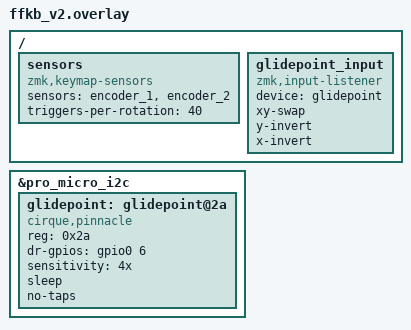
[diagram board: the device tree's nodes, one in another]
#include <dt-bindings/zmk/input_transform.h>

/ {
    sensors {
        compatible = "zmk,keymap-sensors";
        sensors = <&encoder_1 &encoder_2>;
        triggers-per-rotation = <40>;
    };
};

&pro_micro_i2c {
    status = "okay";
    
    glidepoint: glidepoint@2a {
        compatible = "cirque,pinnacle";
        reg = <0x2a>;
        status = "okay";
        // The aforementioned LED data pin that we're not using, hand wired to cirque DR
        dr-gpios = <&gpio0 6 (GPIO_ACTIVE_HIGH)>;

        sensitivity = "4x";
        sleep;
        no-taps;
    };
};

/ {
    glidepoint_input {
        compatible = "zmk,input-listener";
        device = <&glidepoint>;

        xy-swap;
        y-invert;
        x-invert;
    };
};
